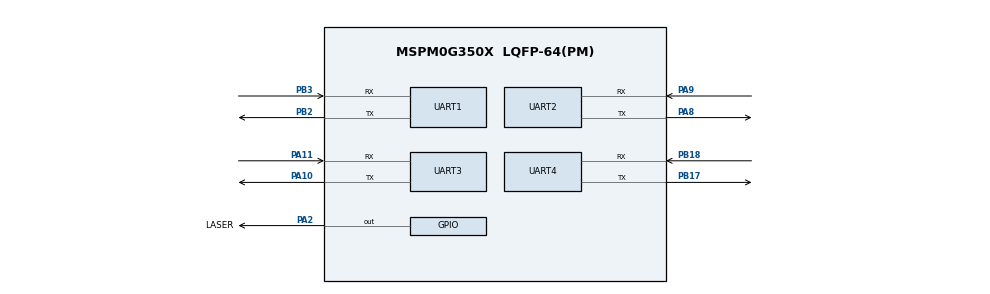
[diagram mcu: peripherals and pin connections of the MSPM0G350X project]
/**
 *
 * @cliArgs --device "MSPM0G350X" --part "Default" --package "LQFP-64(PM)" --product "mspm0_sdk@2.11.00.07"
 * @versions {"tool":"1.28.1+4785"}
 */

/**
 * Import the modules used in this configuration.
 */
const GPIO   = scripting.addModule("/ti/driverlib/GPIO", {}, false);
const GPIO1  = GPIO.addInstance();
const SYSCTL = scripting.addModule("/ti/driverlib/SYSCTL");
const UART   = scripting.addModule("/ti/driverlib/UART", {}, false);
const UART1  = UART.addInstance();
const UART2  = UART.addInstance();
const UART3  = UART.addInstance();
const UART4  = UART.addInstance();

/**
 * Write custom configuration values to the imported modules.
 */
const mux4       = system.clockTree["EXHFMUX"];
mux4.inputSelect = "EXHFMUX_XTAL";

const pinFunction4        = system.clockTree["HFXT"];
pinFunction4.inputFreq    = 40;
pinFunction4.enable       = true;
pinFunction4.HFXTStartup  = 10;
pinFunction4.HFCLKMonitor = true;

GPIO1.$name                              = "GPIO_LASER";
GPIO1.associatedPins[0].$name            = "LASER";
GPIO1.associatedPins[0].assignedPin      = "2";
GPIO1.associatedPins[0].internalResistor = "PULL_DOWN";
GPIO1.associatedPins[0].pin.$assign      = "PA2";

const Board = scripting.addModule("/ti/driverlib/Board", {}, false);

SYSCTL.forceDefaultClkConfig = true;
SYSCTL.CANCLKSource          = "HFCLK";
SYSCTL.useHFCLK_Manual       = true;
SYSCTL.HFCLKSource           = "HFXT";
SYSCTL.HFCLKMonitor          = true;
SYSCTL.HFCLK_Freq            = 40000000;
SYSCTL.clockTreeEn           = true;

UART1.targetBaudRate                   = 115200;
UART1.$name                            = "UART_3";
UART1.enableFIFO                       = true;
UART1.enabledInterrupts                = ["OVERRUN_ERROR","RX"];
UART1.peripheral.$assign               = "UART3";
UART1.peripheral.rxPin.$assign         = "PB3";
UART1.peripheral.txPin.$assign         = "PB2";
UART1.txPinConfig.direction            = scripting.forceWrite("OUTPUT");
UART1.txPinConfig.hideOutputInversion  = scripting.forceWrite(false);
UART1.txPinConfig.onlyInternalResistor = scripting.forceWrite(false);
UART1.txPinConfig.passedPeripheralType = scripting.forceWrite("Digital");
UART1.txPinConfig.$name                = "ti_driverlib_gpio_GPIOPinGeneric0";
UART1.rxPinConfig.hideOutputInversion  = scripting.forceWrite(false);
UART1.rxPinConfig.onlyInternalResistor = scripting.forceWrite(false);
UART1.rxPinConfig.passedPeripheralType = scripting.forceWrite("Digital");
UART1.rxPinConfig.$name                = "ti_driverlib_gpio_GPIOPinGeneric1";

UART2.$name                    = "UART_1";
UART2.targetBaudRate           = 115200;
UART2.enableFIFO               = true;
UART2.enabledInterrupts        = ["OVERRUN_ERROR","RX"];
UART2.peripheral.$assign       = "UART1";
UART2.peripheral.rxPin.$assign = "PA9";
UART2.peripheral.txPin.$assign = "PA8";
UART2.txPinConfig.$name        = "ti_driverlib_gpio_GPIOPinGeneric4";
UART2.rxPinConfig.$name        = "ti_driverlib_gpio_GPIOPinGeneric5";

UART3.$name                            = "UART_0";
UART3.targetBaudRate                   = 115200;
UART3.enabledInterrupts                = ["TX"];
UART3.peripheral.$assign               = "UART0";
UART3.peripheral.rxPin.$assign         = "PA11";
UART3.peripheral.txPin.$assign         = "PA10";
UART3.txPinConfig.$name                = "ti_driverlib_gpio_GPIOPinGeneric6";
UART3.txPinConfig.direction            = scripting.forceWrite("OUTPUT");
UART3.txPinConfig.hideOutputInversion  = scripting.forceWrite(false);
UART3.txPinConfig.onlyInternalResistor = scripting.forceWrite(false);
UART3.txPinConfig.passedPeripheralType = scripting.forceWrite("Digital");
UART3.rxPinConfig.$name                = "ti_driverlib_gpio_GPIOPinGeneric7";
UART3.rxPinConfig.hideOutputInversion  = scripting.forceWrite(false);
UART3.rxPinConfig.onlyInternalResistor = scripting.forceWrite(false);
UART3.rxPinConfig.passedPeripheralType = scripting.forceWrite("Digital");

UART4.$name                            = "UART_2";
UART4.targetBaudRate                   = 115200;
UART4.enableFIFO                       = true;
UART4.enabledInterrupts                = ["OVERRUN_ERROR","RX"];
UART4.peripheral.$assign               = "UART2";
UART4.peripheral.rxPin.$assign         = "PB18";
UART4.peripheral.txPin.$assign         = "PB17";
UART4.txPinConfig.$name                = "ti_driverlib_gpio_GPIOPinGeneric8";
UART4.txPinConfig.direction            = scripting.forceWrite("OUTPUT");
UART4.txPinConfig.hideOutputInversion  = scripting.forceWrite(false);
UART4.txPinConfig.onlyInternalResistor = scripting.forceWrite(false);
UART4.txPinConfig.passedPeripheralType = scripting.forceWrite("Digital");
UART4.rxPinConfig.$name                = "ti_driverlib_gpio_GPIOPinGeneric9";
UART4.rxPinConfig.hideOutputInversion  = scripting.forceWrite(false);
UART4.rxPinConfig.onlyInternalResistor = scripting.forceWrite(false);
UART4.rxPinConfig.passedPeripheralType = scripting.forceWrite("Digital");

/**
 * Pinmux solution for unlocked pins/peripherals. This ensures that minor changes to the automatic solver in a future
 * version of the tool will not impact the pinmux you originally saw.  These lines can be completely deleted in order to
 * re-solve from scratch.
 */
pinFunction4.peripheral.$suggestSolution           = "SYSCTL";
pinFunction4.peripheral.hfxInPin.$suggestSolution  = "PA5";
pinFunction4.peripheral.hfxOutPin.$suggestSolution = "PA6";
Board.peripheral.$suggestSolution                  = "DEBUGSS";
Board.peripheral.swclkPin.$suggestSolution         = "PA20";
Board.peripheral.swdioPin.$suggestSolution         = "PA19";
